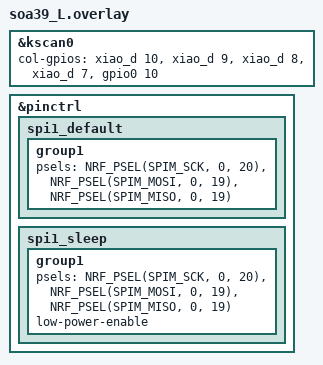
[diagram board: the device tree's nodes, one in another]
#include "soa39.dtsi"

&kscan0 {
        col-gpios
            = <&xiao_d 10 GPIO_ACTIVE_HIGH>
            , <&xiao_d 9 GPIO_ACTIVE_HIGH> 
            , <&xiao_d 8 GPIO_ACTIVE_HIGH> 
            , <&xiao_d 7 GPIO_ACTIVE_HIGH> 
            , <&gpio0 10 GPIO_ACTIVE_HIGH>
            ;
};

// Pin control for SPI1 (WS2812 LED) - like dya-dash
&pinctrl {
    spi1_default: spi1_default {
        group1 {
            psels = <NRF_PSEL(SPIM_SCK, 0, 20)>,
                <NRF_PSEL(SPIM_MOSI, 0, 19)>,
                <NRF_PSEL(SPIM_MISO, 0, 19)>;
        };
    };

    spi1_sleep: spi1_sleep {
        group1 {
            psels = <NRF_PSEL(SPIM_SCK, 0, 20)>,
                <NRF_PSEL(SPIM_MOSI, 0, 19)>,
                <NRF_PSEL(SPIM_MISO, 0, 19)>;
            low-power-enable;
        };
    };
};

